# PIC18F16Q20 register map
Vendor: Microchip
Registers are 8-bit, read-write, reset 0x0 unless marked. A register's access mark holds for its fields unless they carry their own. Addresses are absolute, and some are shared; only a register's first bit layout is shown; [hi:lo] are bit positions; {n}, {i} and the like mark numbered series.

## spi
0x1D7 SPI1RXB ro reset not defined — (power-on value xxxxxxxx)
  [7:0] RXB
0x1D8 SPI1TXB wo reset not defined — (power-on value xxxxxxxx)
  [7:0] TXB
0x1D9 SPI1TCNTL
  [7:0] TCNTL
0x1DA SPI1TCNTH
  [2:0] TCNTH
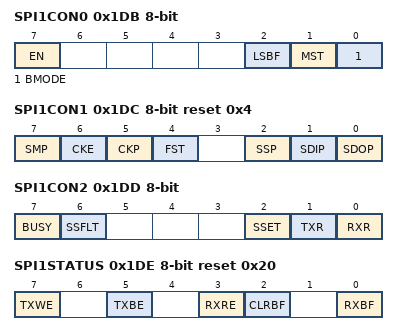
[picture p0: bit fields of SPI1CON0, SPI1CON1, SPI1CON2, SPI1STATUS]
0x1DB SPI1CON0
  [7] EN, [2] LSBF, [1] MST, [0] BMODE
0x1DC SPI1CON1 reset 0x4
  [7] SMP, [6] CKE, [5] CKP, [4] FST, [2] SSP, [1] SDIP, [0] SDOP
0x1DD SPI1CON2
  [7] BUSY ro, [6] SSFLT ro, [2] SSET, [1] TXR, [0] RXR
0x1DE SPI1STATUS reset 0x20
  [7] TXWE — (can only be cleared)
  [5] TXBE ro
  [3] RXRE — (can only be cleared)
  [2] CLRBF — (can only be set)
  [0] RXBF ro
0x1DF SPI1TWIDTH
  [2:0] TWIDTH
0x1E0 SPI1BAUD
  [7:0] BAUD
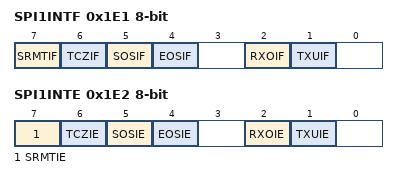
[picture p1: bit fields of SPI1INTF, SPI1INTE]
0x1E1 SPI1INTF
  [7] SRMTIF, [6] TCZIF, [5] SOSIF, [4] EOSIF, [2] RXOIF, [1] TXUIF
0x1E2 SPI1INTE
  [7] SRMTIE, [6] TCZIE, [5] SOSIE, [4] EOSIE, [2] RXOIE, [1] TXUIE
0x1E3 SPI1CLK
  [3:0] CLKSEL

## i2c
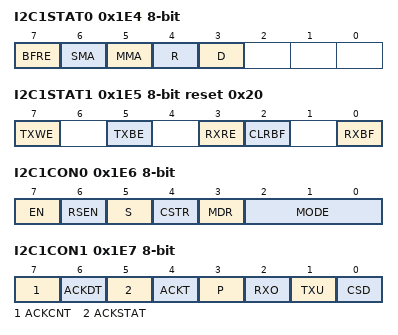
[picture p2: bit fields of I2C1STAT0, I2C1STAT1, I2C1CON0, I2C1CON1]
0x1E4 I2C1STAT0 ro — I2C STATUS REGISTER 0
  [7] BFRE
  [6] SMA
  [5] MMA
  [4] R — Read/Write Information bit
  [3] D — Data/Address bit
0x1E5 I2C1STAT1 reset 0x20 — I2C STATUS REGISTER 1
  [7] TXWE
  [5] TXBE ro
  [3] RXRE
  [2] CLRBF — (can only be set)
  [0] RXBF ro
0x1E6 I2C1CON0 — I2C CONTROL REGISTER 0
  [7] EN
  [6] RSEN
  [5] S — (can only be set)
  [4] CSTR — (can only be cleared)
  [3] MDR ro
  [2:0] MODE
0x1E7 I2C1CON1 — I2C CONTROL REGISTER 1
  [7] ACKCNT
  [6] ACKDT
  [5] ACKSTAT ro
  [4] ACKT ro
  [3] P — (can only be set)
  [2] RXO
  [1] TXU
  [0] CSD
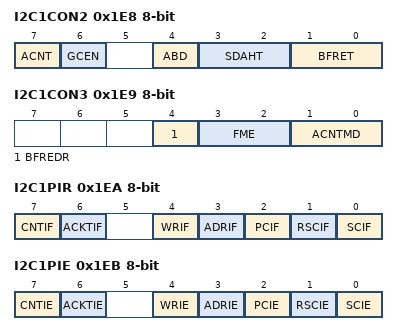
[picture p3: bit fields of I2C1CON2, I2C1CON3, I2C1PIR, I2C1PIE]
0x1E8 I2C1CON2 — I2C CONTROL REGISTER 2
  [7] ACNT, [6] GCEN, [4] ABD, [3:2] SDAHT, [1:0] BFRET
0x1E9 I2C1CON3 — I2C CONTROL REGISTER 3
  [4] BFREDR, [3:2] FME, [1:0] ACNTMD
0x1EA I2C1PIR — I2C PERIPHERAL INTERRUPT FLAG REGISTER
  [7] CNTIF, [6] ACKTIF, [4] WRIF, [3] ADRIF, [2] PCIF, [1] RSCIF, [0] SCIF
0x1EB I2C1PIE — I2C PERIPHERAL INTERRUPT ENABLE REGISTER
  [7] CNTIE, [6] ACKTIE, [4] WRIE, [3] ADRIE, [2] PCIE, [1] RSCIE, [0] SCIE
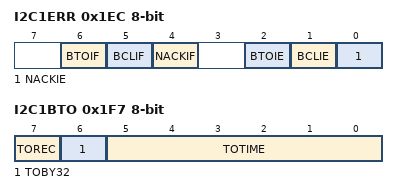
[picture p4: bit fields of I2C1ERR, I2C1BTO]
0x1EC I2C1ERR — I2C ERROR REGISTER
  [6] BTOIF, [5] BCLIF, [4] NACKIF, [2] BTOIE, [1] BCLIE, [0] NACKIE
0x1ED I2C1CNTL reset not defined — I2C BYTE COUNT REGISTER LOW BYTE (power-on value xxxxxxxx)
  [7:0] CNT
0x1EE I2C1CNTH reset not defined — I2C BYTE COUNT REGISTER HIGH BYTE (power-on value xxxxxxxx)
  [7:0] CNT
0x1EF I2C1RXB ro reset not defined — I2C RECEIVE BUFFER REGISTER (power-on value xxxxxxxx)
  [7:0] RXB
0x1F0 I2C1TXB wo reset not defined — I2C TRANSMIT BUFFER REGISTER (power-on value xxxxxxxx)
  [7:0] TXB
0x1F1 I2C1ADB0 reset not defined — I2C ADDRESS BUFFER REGISTER 0 (power-on value xxxxxxxx)
  [7:0] ADB
0x1F2 I2C1ADB1 reset not defined — I2C ADDRESS BUFFER REGISTER 1 (power-on value xxxxxxxx)
  [7:0] ADB
0x1F3 I2C1ADR0 reset 0xFF — I2C ADDRESS REGISTER 0
  [7:0] ADR
0x1F4 I2C1ADR1 reset 0xFE — I2C ADDRESS REGISTER 1
  [7:1] ADR
0x1F5 I2C1ADR2 reset 0xFF — I2C ADDRESS REGISTER 2
  [7:0] ADR
0x1F6 I2C1ADR3 reset 0xFE — I2C ADDRESS REGISTER 3
  [7:1] ADR
0x1F7 I2C1BTO — I2C BUS TIME OUT SELECTION REGISTER
  [7] TOREC, [6] TOBY32, [5:0] TOTIME
0x1F8 I2C1BAUD — I2C BAUD RATE PRESCALER REGISTER
  [7:0] BAUD
0x1F9 I2C1CLK — I2C CLOCK SELECTION REGISTER
  [3:0] CLK
0x1FA I2C1BTOC — I2C BUS TIMEOUT ISM REGISTER
  [2:0] BTOC

## amp_fvr_ts_ctrl
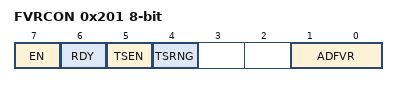
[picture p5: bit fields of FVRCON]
0x201 FVRCON reset not defined — (power-on value xx00--00)
  [7] EN — Zero-Cross Detect Software Enable bit
  [6] RDY ro
  [5] TSEN — Zero-Cross Detect Data Output
  [4] TSRNG — Zero-Cross Detect Polarity bit
  [1:0] ADFVR — Zero-Cross Detect Positive-going Edge Interrupt Enable

## lvd_ctrl
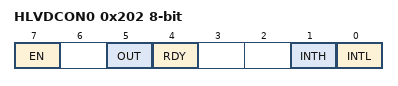
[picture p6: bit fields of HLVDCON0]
0x202 HLVDCON0 reset not defined — (power-on value 0-xx--00)
  [7] EN, [5] OUT ro, [4] RDY ro, [1] INTH, [0] INTL
0x203 HLVDCON1
  [3:0] SEL

## adc_sarcore_mp_ctrl
0x215 ADLTHL
  [7:0] LTH
0x216 ADLTHH
  [7:0] LTH
0x217 ADUTHL
  [7:0] UTH
0x218 ADUTHH
  [7:0] UTH
0x219 ADERRL ro reset not defined — (power-on value xxxxxxxx)
  [7:0] ERR
0x21A ADERRH ro reset not defined — (power-on value xxxxxxxx)
  [7:0] ERR
0x21B ADSTPTL
  [7:0] STPT
0x21C ADSTPTH
  [7:0] STPT
0x21D ADFLTRL ro reset not defined — (power-on value xxxxxxxx)
  [7:0] FLTR
0x21E ADFLTRH ro reset not defined — (power-on value xxxxxxxx)
  [7:0] FLTR
0x21F ADACCL reset not defined — (power-on value xxxxxxxx)
  [7:0] ACC
0x220 ADACCH reset not defined — (power-on value xxxxxxxx)
  [7:0] ACC
0x222 ADCNT
  [7:0] CNT
0x223 ADRPT
  [7:0] RPT
0x224 ADPREVL ro reset not defined — (power-on value xxxxxxxx)
  [7:0] PREV
0x225 ADPREVH ro reset not defined — (power-on value xxxxxxxx)
  [7:0] PREV
0x226 ADRESL reset not defined — (power-on value xxxxxxxx)
  [7:0] RES
0x227 ADRESH reset not defined — (power-on value xxxxxxxx)
  [7:0] RES
0x228 ADPCH
  [5:0] PCH
0x229 ADNCH
  [5:0] NCH
0x22A ADACQL
  [7:0] ACQ
0x22B ADACQH
  [4:0] ACQ
0x22C ADCAP
  [4:0] CAP
0x22D ADPREL
  [7:0] PRE
0x22E ADPREH
  [4:0] PRE
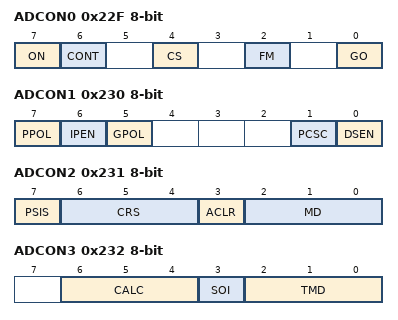
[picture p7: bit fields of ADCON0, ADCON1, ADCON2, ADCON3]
0x22F ADCON0
  [7] ON, [6] CONT, [4] CS, [2] FM, [0] GO
0x230 ADCON1
  [7] PPOL, [6] IPEN, [5] GPOL, [1] PCSC, [0] DSEN
0x231 ADCON2
  [7] PSIS, [6:4] CRS, [3] ACLR, [2:0] MD
0x232 ADCON3
  [6:4] CALC, [3] SOI, [2:0] TMD
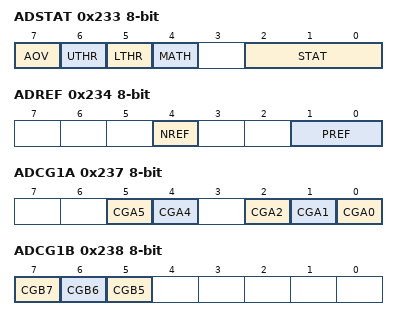
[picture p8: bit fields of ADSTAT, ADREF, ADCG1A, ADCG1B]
0x233 ADSTAT
  [7] AOV ro
  [6] UTHR ro
  [5] LTHR ro
  [4] MATH — (can only be cleared)
  [2:0] STAT ro
0x234 ADREF
  [4] NREF, [1:0] PREF
0x235 ADACT
  [5:0] ACT
0x236 ADCLK
  [5:0] CS
0x237 ADCG1A — ADC CHANNEL GROUP A REGISTER
  [5] CGA5, [4] CGA4, [2] CGA2, [1] CGA1, [0] CGA0
0x238 ADCG1B — ADC CHANNEL GROUP B REGISTER
  [7] CGB7, [6] CGB6, [5] CGB5
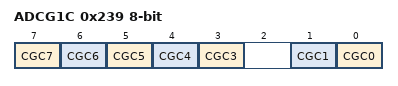
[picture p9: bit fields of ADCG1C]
0x239 ADCG1C — ADC CHANNEL GROUP C REGISTER
  [n] CGC{n} (n=3..7), [1] CGC1, [0] CGC0
